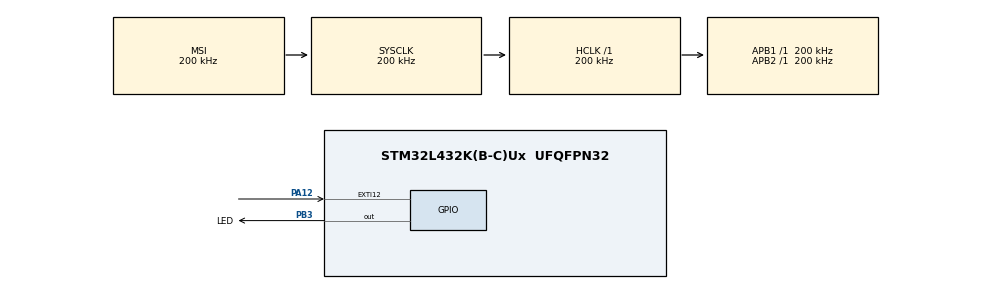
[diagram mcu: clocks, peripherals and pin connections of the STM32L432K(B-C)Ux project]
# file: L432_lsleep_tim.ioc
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Mcu.Family=STM32L4
Mcu.Name=STM32L432K(B-C)Ux
Mcu.Package=UFQFPN32
NVIC.EXTI15_10_IRQn=true\:0\:0\:false\:false\:true\:true\:true
NVIC.PriorityGroup=NVIC_PRIORITYGROUP_4
NVIC.TIM6_DAC_IRQn=true\:0\:0\:false\:false\:true\:true\:true
PA12.Signal=GPXTI12
PA13\ (JTMS-SWDIO).Mode=Serial_Wire
PA13\ (JTMS-SWDIO).Signal=SYS_JTMS-SWDIO
PA14\ (JTCK-SWCLK).Mode=Serial_Wire
PA14\ (JTCK-SWCLK).Signal=SYS_JTCK-SWCLK
PB3\ (JTDO-TRACESWO).GPIO_Label=LED
PB3\ (JTDO-TRACESWO).Signal=GPIO_Output
ProjectManager.HeapSize=0x200
ProjectManager.StackSize=0x400
ProjectManager.TargetToolchain=MDK-ARM V5.27
RCC.ADCFreq_Value=800000
RCC.AHBFreq_Value=200000
RCC.APB1Freq_Value=200000
RCC.APB1TimFreq_Value=200000
RCC.APB2Freq_Value=200000
RCC.APB2TimFreq_Value=200000
RCC.CortexFreq_Value=200000
RCC.HCLKFreq_Value=200000
RCC.HSE_VALUE=8000000
RCC.HSI16_VALUE=16000000
RCC.HSI48_VALUE=48000000
RCC.HSICalibrationValue=0
RCC.HSI_VALUE=16000000
RCC.LSE_VALUE=1000000
RCC.MSIClockRange=RCC_MSIRANGE_1
RCC.MSI_VALUE=200000
RCC.PLLMUL=RCC_PLLMUL_4
RCC.PLLN=16
RCC.SYSCLKFreq_VALUE=200000
RCC.USBFreq_Value=800000
RCC.VCOOutputFreq_Value=3200000
TIM6.Period=20
TIM6.Prescaler=10000
VP_TIM6_VS_ClockSourceINT.Mode=Enable_Timer
board=NUCLEO-L432KC

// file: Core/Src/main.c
/* USER CODE BEGIN Header */
/**
  ******************************************************************************
  * @file           : main.c
  * @brief          : Main program body
  ******************************************************************************
  * @attention
  *
  * <h2><center>&copy; Copyright (c) 2020 STMicroelectronics.
  * All rights reserved.</center></h2>
  *
  * This software component is licensed by ST under BSD 3-Clause license,
  * the "License"; You may not use this file except in compliance with the
  * License. You may obtain a copy of the License at:
  *                        opensource.org/licenses/BSD-3-Clause
  *
  ******************************************************************************
  */
/* USER CODE END Header */
#include "main.h"

TIM_HandleTypeDef htim6;

/* USER CODE BEGIN PV */
static void SystemPower_Config(void);
/* USER CODE END PV */

void SystemClock_Config(void);
static void MX_GPIO_Init(void);
static void MX_TIM6_Init(void);

/* USER CODE BEGIN 0 */
uint8_t uart_buffer[100];
/* USER CODE END 0 */

int main(void)
{

  /* MCU Configuration--------------------------------------------------------*/

  /* Reset of all peripherals, Initializes the Flash interface and the Systick. */
  HAL_Init();

  /* Configure the system clock */
  SystemClock_Config();
	SystemPower_Config();

  /* Initialize all configured peripherals */
  MX_GPIO_Init();
  MX_TIM6_Init();
  /* USER CODE BEGIN 2 */
	__HAL_TIM_CLEAR_IT(&htim6, TIM_SR_UIF);
  __HAL_FLASH_PREFETCH_BUFFER_DISABLE();
  __HAL_FLASH_SLEEP_POWERDOWN_ENABLE();
  /* Reset all RCC Sleep and Stop modes register to */
    /* improve power consumption                      */
    RCC->AHB1SMENR  = 0x0;
    RCC->AHB2SMENR  = 0x0;
    RCC->AHB3SMENR  = 0x0;

    RCC->APB1SMENR1 = 0x0;
    RCC->APB1SMENR2 = 0x0;
    RCC->APB2SMENR  = 0x0;
    HAL_GPIO_WritePin(LED_GPIO_Port, LED_Pin, 1);
    HAL_Delay(5000);
    HAL_GPIO_WritePin(LED_GPIO_Port, LED_Pin, 0);
		HAL_PWR_EnableSleepOnExit();
		HAL_TIM_Base_Start_IT(&htim6);
		__HAL_RCC_TIM6_CLK_SLEEP_ENABLE();
		HAL_SuspendTick();
		HAL_PWR_EnterSLEEPMode(PWR_LOWPOWERREGULATOR_ON, PWR_SLEEPENTRY_WFI);
  /* USER CODE END 2 */

  /* Infinite loop */
  while (1)
  {

  }
}

void SystemClock_Config(void)
{
  RCC_OscInitTypeDef RCC_OscInitStruct = {0};
  RCC_ClkInitTypeDef RCC_ClkInitStruct = {0};

  /** Initializes the RCC Oscillators according to the specified parameters
  * in the RCC_OscInitTypeDef structure.
  */
  RCC_OscInitStruct.OscillatorType = RCC_OSCILLATORTYPE_MSI;
  RCC_OscInitStruct.MSIState = RCC_MSI_ON;
  RCC_OscInitStruct.MSICalibrationValue = 0;
  RCC_OscInitStruct.MSIClockRange = RCC_MSIRANGE_1;
  RCC_OscInitStruct.PLL.PLLState = RCC_PLL_NONE;
  if (HAL_RCC_OscConfig(&RCC_OscInitStruct) != HAL_OK)
  {
    Error_Handler();
  }
  /** Initializes the CPU, AHB and APB buses clocks
  */
  RCC_ClkInitStruct.ClockType = RCC_CLOCKTYPE_HCLK|RCC_CLOCKTYPE_SYSCLK
                              |RCC_CLOCKTYPE_PCLK1|RCC_CLOCKTYPE_PCLK2;
  RCC_ClkInitStruct.SYSCLKSource = RCC_SYSCLKSOURCE_MSI;
  RCC_ClkInitStruct.AHBCLKDivider = RCC_SYSCLK_DIV1;
  RCC_ClkInitStruct.APB1CLKDivider = RCC_HCLK_DIV1;
  RCC_ClkInitStruct.APB2CLKDivider = RCC_HCLK_DIV1;

  if (HAL_RCC_ClockConfig(&RCC_ClkInitStruct, FLASH_LATENCY_0) != HAL_OK)
  {
    Error_Handler();
  }
  /** Configure the main internal regulator output voltage
  */
  if (HAL_PWREx_ControlVoltageScaling(PWR_REGULATOR_VOLTAGE_SCALE1) != HAL_OK)
  {
    Error_Handler();
  }
}

static void MX_TIM6_Init(void)
{

  TIM_MasterConfigTypeDef sMasterConfig = {0};

  htim6.Instance = TIM6;
  htim6.Init.Prescaler = 10000;
  htim6.Init.CounterMode = TIM_COUNTERMODE_UP;
  htim6.Init.Period = 20;
  htim6.Init.AutoReloadPreload = TIM_AUTORELOAD_PRELOAD_DISABLE;
  if (HAL_TIM_Base_Init(&htim6) != HAL_OK)
  {
    Error_Handler();
  }
  sMasterConfig.MasterOutputTrigger = TIM_TRGO_RESET;
  sMasterConfig.MasterSlaveMode = TIM_MASTERSLAVEMODE_DISABLE;
  if (HAL_TIMEx_MasterConfigSynchronization(&htim6, &sMasterConfig) != HAL_OK)
  {
    Error_Handler();
  }

}

static void MX_GPIO_Init(void)
{
  GPIO_InitTypeDef GPIO_InitStruct = {0};

  /* GPIO Ports Clock Enable */
  __HAL_RCC_GPIOA_CLK_ENABLE();
  __HAL_RCC_GPIOB_CLK_ENABLE();

  /*Configure GPIO pin Output Level */
  HAL_GPIO_WritePin(LED_GPIO_Port, LED_Pin, GPIO_PIN_RESET);

  /*Configure GPIO pin : PA12 */
  GPIO_InitStruct.Pin = GPIO_PIN_12;
  GPIO_InitStruct.Mode = GPIO_MODE_IT_RISING;
  GPIO_InitStruct.Pull = GPIO_NOPULL;
  HAL_GPIO_Init(GPIOA, &GPIO_InitStruct);

  /*Configure GPIO pin : LED_Pin */
  GPIO_InitStruct.Pin = LED_Pin;
  GPIO_InitStruct.Mode = GPIO_MODE_OUTPUT_PP;
  GPIO_InitStruct.Pull = GPIO_NOPULL;
  GPIO_InitStruct.Speed = GPIO_SPEED_FREQ_LOW;
  HAL_GPIO_Init(LED_GPIO_Port, &GPIO_InitStruct);

  /* EXTI interrupt init*/
  HAL_NVIC_SetPriority(EXTI15_10_IRQn, 0, 0);
  HAL_NVIC_EnableIRQ(EXTI15_10_IRQn);

}

/* USER CODE BEGIN 4 */

static void SystemPower_Config(void)
{
  GPIO_InitTypeDef GPIO_InitStructure;

  /* Enable Power Clock */
  __HAL_RCC_PWR_CLK_ENABLE();

/* Enable GPIOs clock */
    __HAL_RCC_GPIOA_CLK_ENABLE();
    __HAL_RCC_GPIOB_CLK_ENABLE();
    __HAL_RCC_GPIOC_CLK_ENABLE();
    __HAL_RCC_GPIOH_CLK_ENABLE();

    /* Configure all GPIO port pins in Analog Input mode (floating input trigger OFF) */
    /* Note: Debug using ST-Link is not possible during the execution of this   */
    /*       example because communication between ST-link and the device       */
    /*       under test is done through UART. All GPIO pins are disabled (set   */
    /*       to analog input mode) including  UART I/O pins.           */
    GPIO_InitStructure.Pin = GPIO_PIN_All;
    GPIO_InitStructure.Mode = GPIO_MODE_ANALOG;
    GPIO_InitStructure.Pull = GPIO_NOPULL;

    HAL_GPIO_Init(GPIOA, &GPIO_InitStructure);
    HAL_GPIO_Init(GPIOB, &GPIO_InitStructure);
    HAL_GPIO_Init(GPIOC, &GPIO_InitStructure);
    HAL_GPIO_Init(GPIOH, &GPIO_InitStructure);

    /* Disable GPIOs clock */
    __HAL_RCC_GPIOA_CLK_DISABLE();
    __HAL_RCC_GPIOB_CLK_DISABLE();
    __HAL_RCC_GPIOC_CLK_DISABLE();
    __HAL_RCC_GPIOH_CLK_DISABLE();
}

void HAL_TIM_PeriodElapsedCallback(TIM_HandleTypeDef *htim) {
	HAL_GPIO_TogglePin(LED_GPIO_Port, LED_Pin);
}

/* USER CODE END 4 */

void Error_Handler(void)
{
}

/************************ (C) COPYRIGHT STMicroelectronics *****END OF FILE****/
